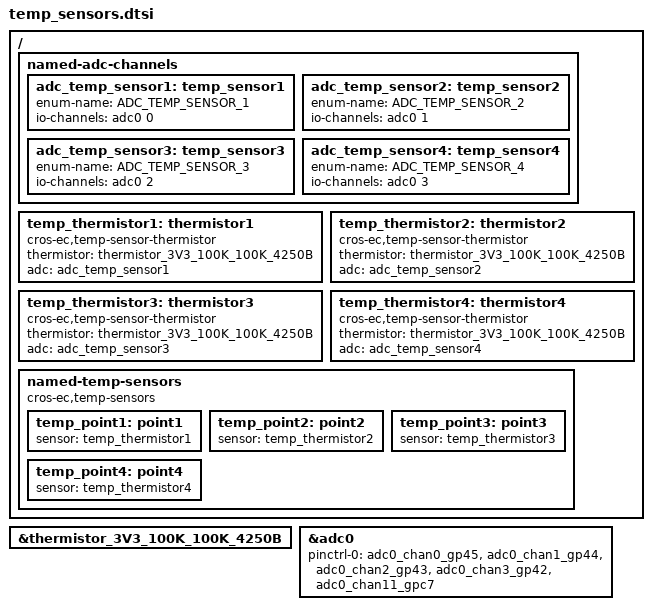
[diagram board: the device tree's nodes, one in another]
/* Copyright 2025 The ChromiumOS Authors
 * Use of this source code is governed by a BSD-style license that can be
 * found in the LICENSE file.
 */
 #include <cros/thermistor/thermistor.dtsi>

/ {
	named-adc-channels {

		adc_temp_sensor1: temp_sensor1 {
			enum-name = "ADC_TEMP_SENSOR_1";
			io-channels = <&adc0 0>;
		};
		adc_temp_sensor2: temp_sensor2 {
			enum-name = "ADC_TEMP_SENSOR_2";
			io-channels = <&adc0 1>;
		};
		adc_temp_sensor3: temp_sensor3 {
			enum-name = "ADC_TEMP_SENSOR_3";
			io-channels = <&adc0 2>;
		};
		adc_temp_sensor4: temp_sensor4 {
			enum-name = "ADC_TEMP_SENSOR_4";
			io-channels = <&adc0 3>;
		};
	};

	temp_thermistor1: thermistor1 {
		compatible = "cros-ec,temp-sensor-thermistor";
		thermistor = <&thermistor_3V3_100K_100K_4250B>;
		adc = <&adc_temp_sensor1>;
	};
	temp_thermistor2: thermistor2 {
		compatible = "cros-ec,temp-sensor-thermistor";
		thermistor = <&thermistor_3V3_100K_100K_4250B>;
		adc = <&adc_temp_sensor2>;
	};
	temp_thermistor3: thermistor3 {
		compatible = "cros-ec,temp-sensor-thermistor";
		thermistor = <&thermistor_3V3_100K_100K_4250B>;
		adc = <&adc_temp_sensor3>;
	};
	temp_thermistor4: thermistor4 {
		compatible = "cros-ec,temp-sensor-thermistor";
		thermistor = <&thermistor_3V3_100K_100K_4250B>;
		adc = <&adc_temp_sensor4>;
	};

	named-temp-sensors {
		compatible = "cros-ec,temp-sensors";
		temp_point1: point1 {
			sensor = <&temp_thermistor1>;
		};
		temp_point2: point2 {
			sensor = <&temp_thermistor2>;
		};
		temp_point3: point3 {
			sensor = <&temp_thermistor3>;
		};
		temp_point4: point4 {
			sensor = <&temp_thermistor4>;
		};
	};
};

&thermistor_3V3_100K_100K_4250B {
	status = "okay";
};

&adc0 {
	pinctrl-0 = <&adc0_chan0_gp45
		&adc0_chan1_gp44
		&adc0_chan2_gp43
		&adc0_chan3_gp42
		&adc0_chan11_gpc7>;
	pinctrl-names = "default";
};
